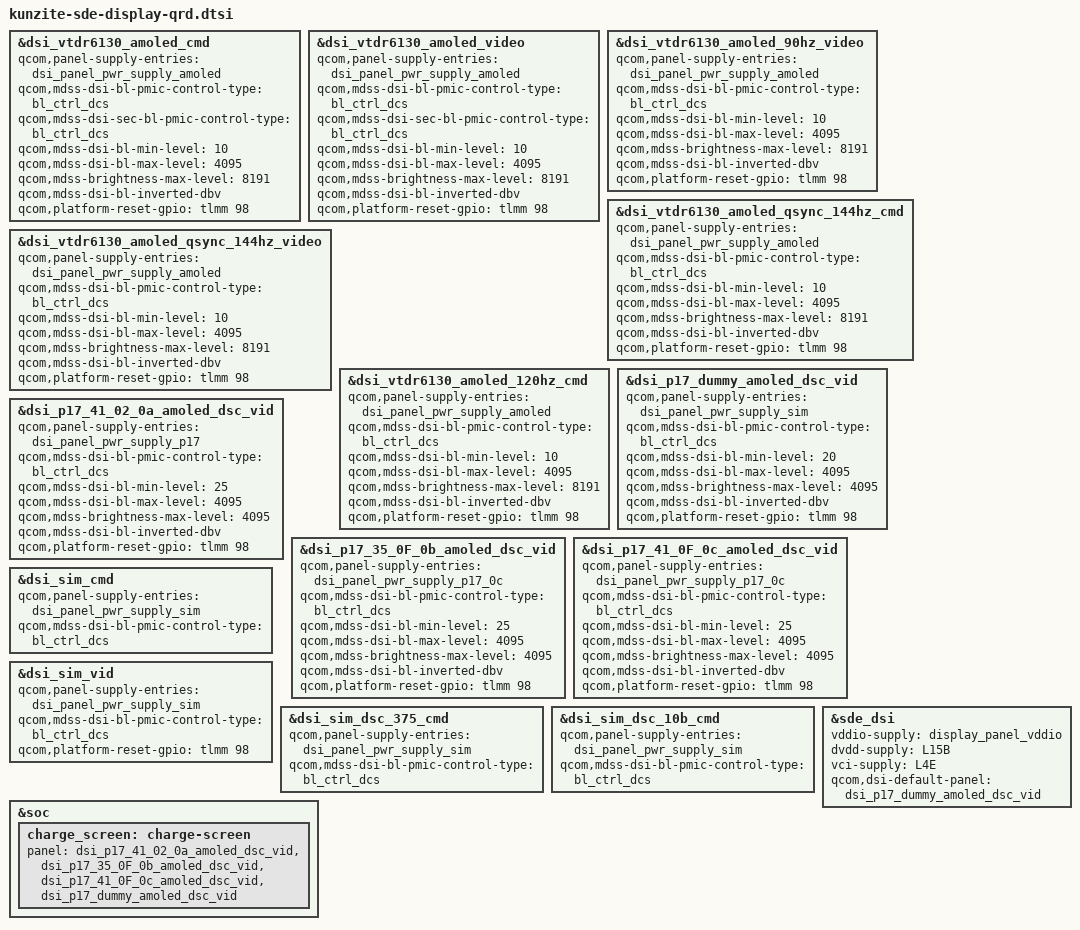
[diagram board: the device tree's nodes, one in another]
#include "parrot-sde-display.dtsi"
#include "touchscreen.dtsi"

&dsi_vtdr6130_amoled_cmd {
	qcom,panel-supply-entries = <&dsi_panel_pwr_supply_amoled>;
	qcom,mdss-dsi-bl-pmic-control-type = "bl_ctrl_dcs";
	qcom,mdss-dsi-sec-bl-pmic-control-type = "bl_ctrl_dcs";
	qcom,mdss-dsi-bl-min-level = <10>;
	qcom,mdss-dsi-bl-max-level = <4095>;
	qcom,mdss-brightness-max-level = <8191>;
	qcom,mdss-dsi-bl-inverted-dbv;
	qcom,platform-reset-gpio = <&tlmm 98 0>;
};

&dsi_vtdr6130_amoled_video {
	qcom,panel-supply-entries = <&dsi_panel_pwr_supply_amoled>;
	qcom,mdss-dsi-bl-pmic-control-type = "bl_ctrl_dcs";
	qcom,mdss-dsi-sec-bl-pmic-control-type = "bl_ctrl_dcs";
	qcom,mdss-dsi-bl-min-level = <10>;
	qcom,mdss-dsi-bl-max-level = <4095>;
	qcom,mdss-brightness-max-level = <8191>;
	qcom,mdss-dsi-bl-inverted-dbv;
	qcom,platform-reset-gpio = <&tlmm 98 0>;
};

&dsi_vtdr6130_amoled_90hz_video {
	qcom,panel-supply-entries = <&dsi_panel_pwr_supply_amoled>;
	qcom,mdss-dsi-bl-pmic-control-type = "bl_ctrl_dcs";
	qcom,mdss-dsi-bl-min-level = <10>;
	qcom,mdss-dsi-bl-max-level = <4095>;
	qcom,mdss-brightness-max-level = <8191>;
	qcom,mdss-dsi-bl-inverted-dbv;
	qcom,platform-reset-gpio = <&tlmm 98 0>;
};

&dsi_vtdr6130_amoled_qsync_144hz_cmd {
	qcom,panel-supply-entries = <&dsi_panel_pwr_supply_amoled>;
	qcom,mdss-dsi-bl-pmic-control-type = "bl_ctrl_dcs";
	qcom,mdss-dsi-bl-min-level = <10>;
	qcom,mdss-dsi-bl-max-level = <4095>;
	qcom,mdss-brightness-max-level = <8191>;
	qcom,mdss-dsi-bl-inverted-dbv;
	qcom,platform-reset-gpio = <&tlmm 98 0>;
};

&dsi_vtdr6130_amoled_qsync_144hz_video {
	qcom,panel-supply-entries = <&dsi_panel_pwr_supply_amoled>;
	qcom,mdss-dsi-bl-pmic-control-type = "bl_ctrl_dcs";
	qcom,mdss-dsi-bl-min-level = <10>;
	qcom,mdss-dsi-bl-max-level = <4095>;
	qcom,mdss-brightness-max-level = <8191>;
	qcom,mdss-dsi-bl-inverted-dbv;
	qcom,platform-reset-gpio = <&tlmm 98 0>;
};

&dsi_vtdr6130_amoled_120hz_cmd {
	qcom,panel-supply-entries = <&dsi_panel_pwr_supply_amoled>;
	qcom,mdss-dsi-bl-pmic-control-type = "bl_ctrl_dcs";
	qcom,mdss-dsi-bl-min-level = <10>;
	qcom,mdss-dsi-bl-max-level = <4095>;
	qcom,mdss-brightness-max-level = <8191>;
	qcom,mdss-dsi-bl-inverted-dbv;
	qcom,platform-reset-gpio = <&tlmm 98 0>;
};

&dsi_p17_dummy_amoled_dsc_vid {
	qcom,panel-supply-entries = <&dsi_panel_pwr_supply_sim>;
	qcom,mdss-dsi-bl-pmic-control-type = "bl_ctrl_dcs";
	qcom,mdss-dsi-bl-min-level = <20>;
	qcom,mdss-dsi-bl-max-level = <4095>;
	qcom,mdss-brightness-max-level = <4095>;
	qcom,mdss-dsi-bl-inverted-dbv;
	qcom,platform-reset-gpio = <&tlmm 98 0>;
};

&dsi_p17_41_02_0a_amoled_dsc_vid {
	qcom,panel-supply-entries = <&dsi_panel_pwr_supply_p17>;
	qcom,mdss-dsi-bl-pmic-control-type = "bl_ctrl_dcs";
	qcom,mdss-dsi-bl-min-level = <25>;
	qcom,mdss-dsi-bl-max-level = <4095>;
	qcom,mdss-brightness-max-level = <4095>;
	qcom,mdss-dsi-bl-inverted-dbv;
	qcom,platform-reset-gpio = <&tlmm 98 0>;
};

&dsi_p17_35_0F_0b_amoled_dsc_vid {
	qcom,panel-supply-entries = <&dsi_panel_pwr_supply_p17_0c>;
	qcom,mdss-dsi-bl-pmic-control-type = "bl_ctrl_dcs";
	qcom,mdss-dsi-bl-min-level = <25>;
	qcom,mdss-dsi-bl-max-level = <4095>;
	qcom,mdss-brightness-max-level = <4095>;
	qcom,mdss-dsi-bl-inverted-dbv;
	qcom,platform-reset-gpio = <&tlmm 98 0>;
};

&dsi_p17_41_0F_0c_amoled_dsc_vid {
	qcom,panel-supply-entries = <&dsi_panel_pwr_supply_p17_0c>;
	qcom,mdss-dsi-bl-pmic-control-type = "bl_ctrl_dcs";
	qcom,mdss-dsi-bl-min-level = <25>;
	qcom,mdss-dsi-bl-max-level = <4095>;
	qcom,mdss-brightness-max-level = <4095>;
	qcom,mdss-dsi-bl-inverted-dbv;
	qcom,platform-reset-gpio = <&tlmm 98 0>;
};

&dsi_sim_cmd {
	qcom,panel-supply-entries = <&dsi_panel_pwr_supply_sim>;
	qcom,mdss-dsi-bl-pmic-control-type = "bl_ctrl_dcs";
};

&dsi_sim_vid {
	qcom,panel-supply-entries = <&dsi_panel_pwr_supply_sim>;
	qcom,mdss-dsi-bl-pmic-control-type = "bl_ctrl_dcs";
	qcom,platform-reset-gpio = <&tlmm 98 0>;
};

&dsi_sim_dsc_375_cmd {
	qcom,panel-supply-entries = <&dsi_panel_pwr_supply_sim>;
	qcom,mdss-dsi-bl-pmic-control-type = "bl_ctrl_dcs";
};

&dsi_sim_dsc_10b_cmd {
	qcom,panel-supply-entries = <&dsi_panel_pwr_supply_sim>;
	qcom,mdss-dsi-bl-pmic-control-type = "bl_ctrl_dcs";
};

&sde_dsi {
	vddio-supply = <&display_panel_vddio>;
	dvdd-supply = <&L15B>;
	vci-supply = <&L4E>;

	qcom,dsi-default-panel = <&dsi_p17_dummy_amoled_dsc_vid>;
};

/*&qupv3_se9_spi {
	goodix-berlin@0 {
		panel = <&dsi_vtdr6130_amoled_cmd
			&dsi_vtdr6130_amoled_video
			&dsi_vtdr6130_amoled_qsync_144hz_cmd
			&dsi_vtdr6130_amoled_qsync_144hz_video
			&dsi_vtdr6130_amoled_120hz_cmd
			&dsi_vtdr6130_amoled_90hz_video>;
	};
};*/

&soc {
	charge_screen: charge-screen {
		panel  = <&dsi_p17_41_02_0a_amoled_dsc_vid
			&dsi_p17_35_0F_0b_amoled_dsc_vid
			&dsi_p17_41_0F_0c_amoled_dsc_vid
			&dsi_p17_dummy_amoled_dsc_vid>;
	};
};
